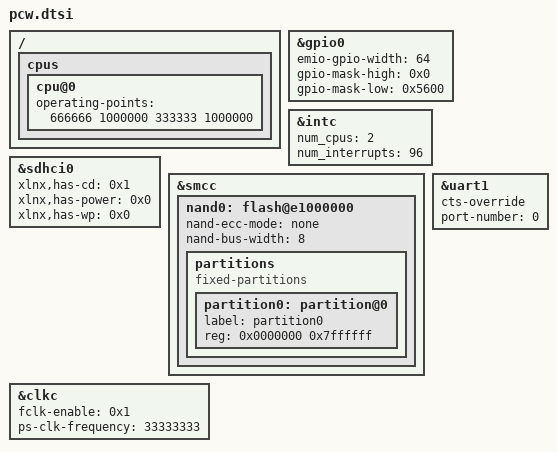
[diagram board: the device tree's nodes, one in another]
/*
 * CAUTION: This file is automatically generated by Xilinx.
 * Version: XSCT 2023.2
 * Today is: Sat Jan  6 13:00:35 2024
 */


/ {
	cpus {
		cpu@0 {
			operating-points = <666666 1000000 333333 1000000>;
		};
	};
};
&gpio0 {
	emio-gpio-width = <64>;
	gpio-mask-high = <0x0>;
	gpio-mask-low = <0x5600>;
};
&intc {
	num_cpus = <2>;
	num_interrupts = <96>;
};
&sdhci0 {
	status = "okay";
	xlnx,has-cd = <0x1>;
	xlnx,has-power = <0x0>;
	xlnx,has-wp = <0x0>;
};
&smcc {
	status = "okay";
	nand0: flash@e1000000 {
                status = "okay";
                nand-ecc-mode = "none";
                nand-bus-width = <8>;
                partitions {
        		compatible = "fixed-partitions";
        		#address-cells = <1>;
        		#size-cells = <1>;
                
                        partition0: partition@0 {
        		         label = "partition0";
                                 reg = <0x0000000 0x7ffffff>;
                        };
                };
        };
};
&uart1 {
	cts-override ;
	device_type = "serial";
	port-number = <0>;
	status = "okay";
};
&clkc {
	fclk-enable = <0x1>;
	ps-clk-frequency = <33333333>;
};
